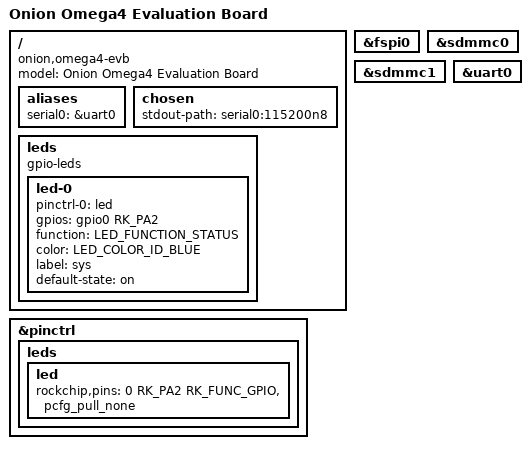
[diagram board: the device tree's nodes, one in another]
// SPDX-License-Identifier: (GPL-2.0+ OR MIT)
/*
 * Copyright (c) 2022 Rockchip Electronics Co., Ltd.
 * Copyright (c) 2025 plan44.ch/luz
 * Copyright (c) 2026 Onion Corporation
 */

/dts-v1/;

#include <dt-bindings/gpio/gpio.h>
#include <dt-bindings/leds/common.h>
#include "rv1103b-omega4.dtsi"

/ {
	model = "Onion Omega4 Evaluation Board";
	compatible = "onion,omega4-evb", "onion,omega4", "rockchip,rv1103b";

	aliases {
		serial0 = &uart0;
	};

	chosen {
		stdout-path = "serial0:115200n8";
	};

	leds {
		compatible = "gpio-leds";

		led-0	{
			pinctrl-names = "default";
			pinctrl-0 = <&led>;
			gpios = <&gpio0 RK_PA2 GPIO_ACTIVE_HIGH>;
			function = LED_FUNCTION_STATUS;
			color = <LED_COLOR_ID_BLUE>;
			label = "sys";
			default-state = "on";
		};
	};
};

&fspi0 {
	status = "okay";
};

&sdmmc0 {
	status = "okay";
};

&sdmmc1 {
	status = "okay";
};

&uart0 {
	status = "okay";
};

&pinctrl {
	leds {
		led: led {
			rockchip,pins = <0 RK_PA2 RK_FUNC_GPIO &pcfg_pull_none>;
		};
	};
};
